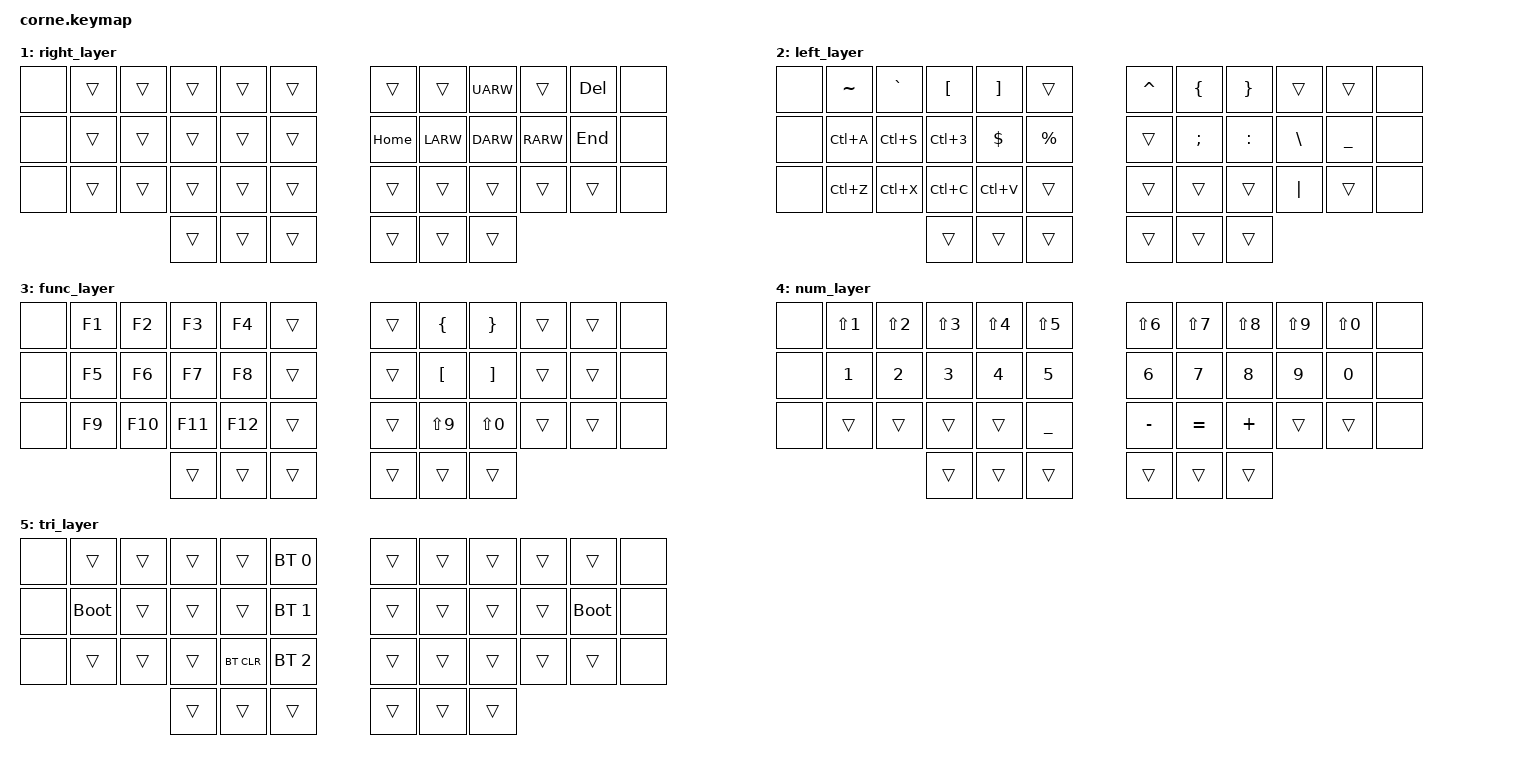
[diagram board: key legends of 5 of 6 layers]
/*
 * Copyright (c) 2020 The ZMK Contributors
 *
 * SPDX-License-Identifier: MIT
 */

#include <behaviors.dtsi>
#include <dt-bindings/zmk/keys.h>
#include <dt-bindings/zmk/bt.h>

// Home row mods macro
#define HRML(k1,k2,k3,k4) &ht LSHFT k1  &ht LALT k2  &ht LCTRL k3  &ht LGUI k4
#define HRMR(k1,k2,k3,k4) &ht RGUI k1  &ht RCTRL k2  &ht RALT k3  &ht RSHFT k4
// combos
#define COMBO(NAME, KEYPOS) \
  combo_##NAME { \
      timeout-ms = <40>; \
      key-positions = <KEYPOS>; \
      bindings = <&kp NAME>; \
  };


// Using layer taps on thumbs, having quick tap as well helps w/ repeating space/backspace
&lt { quick_tap_ms = <200>; };
&mt { quick_tap_ms = <50>; };


/ {
    behaviors {
        ht: hold_tap {
            label = "hold_tap";
            compatible = "zmk,behavior-hold-tap";
            #binding-cells = <2>;
            flavor = "tap-preferred";
            tapping-term-ms = <220>;
            quick-tap-ms = <150>;
            global-quick-tap;
            bindings = <&kp>, <&kp>;
        };
    };

    conditional_layers {
        compatible = "zmk,conditional-layers";
        tri_layer {
            if-layers = <1 3>;
            then-layer = <5>;
        };
    };

    combos {
      compatible = "zmk,combos";
      
      // Left-hand combos
      COMBO(TAB, 15 16)
      //COMBO(LEFT_BRACE, 2 3)

      // Right-hand combos

    };



        //  ╭──────────┬──────────┬──────────┬──────────┬──────────╮   ╭──────────┬──────────┬──────────┬──────────┬───────────╮
        // 0│   1      │  2       │  3       │  4       │ 5        │   │  6       │  7       │  8       │  9       │ 10        │11
        //  ├──────────┼──────────┼──────────┼──────────┼──────────┤   ├──────────┼──────────┼──────────┼──────────┼───────────┤
        //12│  13      │ 14       │ 15       │ 16       │ 17       │   │ 18       │ 19       │ 20       │ 21       │ 22        |23
        //  ├──────────┼──────────┼──────────┼──────────┼──────────┤   ├──────────┼──────────┼──────────┼──────────┼───────────┤
        //24│  25      │ 26       │ 27       │ 28       │ 29       │   │ 30       │ 31       │ 32       │ 33       │ 34        |35
        //  ╰──────────┴──────────┼──────────┼──────────┼──────────┤   ├──────────┼──────────┼──────────┼──────────┴───────────╯
        //                        | 36       | 37       | 38       |   | 39       | 40       | 41       |
        //                        ╰──────────┴──────────┴──────────╯   ╰──────────┴──────────┴──────────╯




        keymap {
                compatible = "zmk,keymap";

            default_layer {
            bindings = <
        //╭──────────┬──────────┬──────────┬──────────┬──────────╮   ╭──────────┬──────────┬──────────┬──────────┬──────────╮
        //│  Q       │  W       │  E       │  R       │  T       │   │  Y       │  U       │  I       │  O       │  P       │
     &none   &kp Q      &kp W      &kp E      &kp R      &kp T          &kp Y      &kp U      &kp I      &kp O      &kp P        &none 
        //├──────────┼──────────┼──────────┼──────────┼──────────┤   ├──────────┼──────────┼──────────┼──────────┼──────────┤
        //│  A       │  S       │  D       │  F       │  G       │   │  H       │  J       │  K       │  L       │ ' "      │
     &none   HRML(A,        S,         D,         F)     &kp G          &kp H       &kp J     &kp K       &kp L   &ht RSHFT SQT  &none 
        //├──────────┼──────────┼──────────┼──────────┼──────────┤   ├──────────┼──────────┼──────────┼──────────┼──────────┤
        //│  Z       │  X       │  C       │  V       │  B       │   │  N       │  M       │ , <      │ . >      │ / ?      │
     &none  &kp Z      &kp X      &kp C      &kp V      &kp B          &kp N      &kp M      &kp COMMA  &kp DOT    &kp FSLH     &none 
        //╰──────────┴──────────┴──────────┼──────────┼──────────┤   ├──────────┼──────────┼──────────┴──────────┴──────────╯
        //                      | 36       | 37       | 38       |   | 39       | 40       | 41       |
                                 &kp LALT   &lt 3 ESC  &lt 2 SPACE    &lt 4 BSPC &lt 1 ENTER  &kp LGUI
        //                      ╰──────────┴──────────┴──────────╯   ╰──────────┴──────────┴──────────╯
            >;
        };

        right_layer {
            bindings = <
        //╭──────────┬──────────┬──────────┬──────────┬──────────╮   ╭──────────┬──────────┬──────────┬──────────┬──────────╮
        //│          │          │          │          │          │   │          │          │ UP       │          │  DEL     │
&none        &trans    &trans     &trans     &trans     &trans          &trans     &trans     &kp UARW   &trans    &kp DEL     &none 
        //├──────────┼──────────┼──────────┼──────────┼──────────┤   ├──────────┼──────────┼──────────┼──────────┼──────────┤
        //│          │          │          │          │          │   │ HOME     │ LEFT     │ DOWN     │ RIGHT    │ END      │
&none        &trans     &trans     &trans     &trans     &trans         &kp HOME   &kp LARW   &kp DARW   &kp RARW   &kp END    &none 
        //├──────────┼──────────┼──────────┼──────────┼──────────┤   ├──────────┼──────────┼──────────┼──────────┼──────────┤
        //│          │          │          │          │          │   │          │          │          │          │          │
&none        &trans     &trans     &trans     &trans     &trans         &trans     &trans     &trans     &trans     &trans     &none 
        //╰──────────┴──────────┴──────────┼──────────┼──────────┤   ├──────────┼──────────┼──────────┴──────────┴──────────╯
                                  &trans      &trans     &trans         &trans     &trans    &trans
        //                      ╰──────────┴──────────┴──────────╯   ╰──────────┴──────────┴──────────╯
            >;
        };

        left_layer {
            bindings = <
        //╭──────────┬──────────┬──────────┬──────────┬──────────╮   ╭──────────┬──────────┬──────────┬──────────┬──────────╮
        //│  ~       │   `      │  [       │  ]       │          │   │  ^       │  {       │  }       │          │          │
&none      &kp TILDE   &kp GRAVE   &kp LBKT   &kp RBKT   &trans        &kp CARET  &kp LBRC   &kp RBRC   &trans      &trans   &none 
        //├──────────┼──────────┼──────────┼──────────┼──────────┤   ├──────────┼──────────┼──────────┼──────────┼──────────┤
        //│ CTRL A   │ CTRL S   │ CTRL D   │  $       │  %       │   │          │   ;      │   :      │  \       │   _      │
&none       &kp LC(A)  &kp LC(S) &kp LC(N3)  &kp DLLR   &kp PRCNT      &trans    &kp SEMI   &kp COLON  &kp BSLH   &kp UNDER    &none 
        //├──────────┼──────────┼──────────┼──────────┼──────────┤   ├──────────┼──────────┼──────────┼──────────┼──────────┤
        //│ CTRL Z   │ CTRL X   │ CTRL C   │ CTRL V   │          │   │          │          │          │  │       │          │
&none      &kp LC(Z) &kp LC(X)   &kp LC(C)  &kp LC(V)   &trans         &trans    &trans     &trans     &kp PIPE     &trans   &none 
        //╰──────────┴──────────┴──────────┼──────────┼──────────┤   ├──────────┼──────────┼──────────┴──────────┴──────────╯
                                  &trans      &trans     &trans         &trans     &trans    &trans
        //                      ╰──────────┴──────────┴──────────╯   ╰──────────┴──────────┴──────────╯
            >;
        };

       func_layer {
            bindings = <
        //╭──────────┬──────────┬──────────┬──────────┬──────────╮   ╭──────────┬──────────┬──────────┬──────────┬──────────╮
        //│ F1       │ F2       │ F3       │ F4       │          │   │          │    {     │    }     │          │          │
&none       &kp F1     &kp F2     &kp F3     &kp F4     &trans         &trans    &kp LBRC   &kp RBRC    &trans     &trans   &none 
        //├──────────┼──────────┼──────────┼──────────┼──────────┤   ├──────────┼──────────┼──────────┼──────────┼──────────┤
        //│ F5       │ F6       │ F7       │ F8       |          │   │          │    [     │    ]     │          │          │
&none       &kp F5     &kp F6     &kp F7     &kp F8     &trans         &trans    &kp LBKT    &kp RBKT   &trans     &trans   &none 
        //├──────────┼──────────┼──────────┼──────────┼──────────┤   ├──────────┼──────────┼──────────┼──────────┼──────────┤
        //│ F9       │ F10      │ F11      │ F12      │          │   │          │    (     │    )     │          │          │
&none       &kp F9     &kp F10    &kp F11    &kp F12    &trans         &trans    &kp LS(N9)  &kp LS(N0)  &trans     &trans   &none 
        //╰──────────┴──────────┴──────────┼──────────┼──────────┤   ├──────────┼──────────┼──────────┴──────────┴──────────╯
                                  &trans      &trans     &trans         &trans     &trans    &trans
        //                      ╰──────────┴──────────┴──────────╯   ╰──────────┴──────────┴──────────╯
            >;
        };

        num_layer {
            bindings = <
        //╭──────────┬──────────┬──────────┬──────────┬──────────╮   ╭──────────┬──────────┬──────────┬──────────┬──────────╮
        //│ !        │ @        │  #       │ $        | %        │   │ ^        │  &       │  *       │ (        │ )        │
&none      &kp LS(N1) &kp LS(N2) &kp LS(N3) &kp LS(N4) &kp LS(N5)     &kp LS(N6) &kp LS(N7) &kp LS(N8) &kp LS(N9) &kp LS(N0)   &none 
        //├──────────┼──────────┼──────────┼──────────┼──────────┤   ├──────────┼──────────┼──────────┼──────────┼──────────┤
        //│ 1        │ 2        │ 3        │ 4        | 5        │   │ 6        │ 7        │ 8        │ 9        │ 0        │
&none       &kp N1     &kp N2     &kp N3     &kp N4     &kp N5         &kp N6     &kp N7      &kp N8     &kp N9      &kp N0    &none 
        //├──────────┼──────────┼──────────┼──────────┼──────────┤   ├──────────┼──────────┼──────────┼──────────┼──────────┤
        //│          │          │          │          │     _    │   │    -     │    =     │    +     │          │          │
&none       &trans     &trans     &trans     &trans     &kp UNDER     &kp MINUS  &kp EQUAL  &kp PLUS     &trans     &trans     &none 
        //╰──────────┴──────────┴──────────┼──────────┼──────────┤   ├──────────┼──────────┼──────────┴──────────┴──────────╯
                                  &trans      &trans     &trans         &trans     &trans    &trans
        //                      ╰──────────┴──────────┴──────────╯   ╰──────────┴──────────┴──────────╯
            >;
        };

        tri_layer {
            bindings = <
        //╭──────────┬──────────┬──────────┬──────────┬──────────╮   ╭──────────┬──────────┬──────────┬──────────┬──────────╮
        //│          │          │          │          │PROFILE 0 │   │          │          │          │          │          │
&none       &trans     &trans     &trans     &trans    &bt BT_SEL 0    &trans     &trans     &trans     &trans      &trans    &none 
        //├──────────┼──────────┼──────────┼──────────┼──────────┤   ├──────────┼──────────┼──────────┼──────────┼──────────┤
        //│BOOTLOADER│          │          │          │PROFILE 1 │   │          │          │          │          │BOOTLOADER│
&none      &bootloader  &trans     &trans     &trans    &bt BT_SEL 1    &trans     &trans     &trans     &trans    &bootloader &none 
        //├──────────┼──────────┼──────────┼──────────┼──────────┤   ├──────────┼──────────┼──────────┼──────────┼──────────┤
        //│          │          │          │ CLEAR BT │PROFILE 2 │   │          │          │          │          │          │
&none       &trans     &trans     &trans    &bt BT_CLR &bt BT_SEL 2    &trans     &trans     &trans     &trans     &trans      &none 
        //╰──────────┴──────────┴──────────┼──────────┼──────────┤   ├──────────┼──────────┼──────────┴──────────┴──────────╯
                                  &trans      &trans     &trans         &trans     &trans    &trans
        //                      ╰──────────┴──────────┴──────────╯   ╰──────────┴──────────┴──────────╯
            >;
        };
        };
};
